VERSION ""

NS_ :

BS_:

BU_:
VAL_TABLE_ Speed ;

BO_ 0 ThrottleMsg: 1 Vector__XXX
 SG_ IntakeValve : 1|7@1+ (1,0) [0|90] "degree" Vector__XXX
 SG_ ThrottlePosition : 0|1@1+ (1,0) [0|1] "Boolean" Vector__XXX

BO_ 256 BrakeMsg: 1 Vector__XXX
 SG_ Brake_Status : 0|1@1+ (1,0) [0|1] "Boolean" Vector__XXX

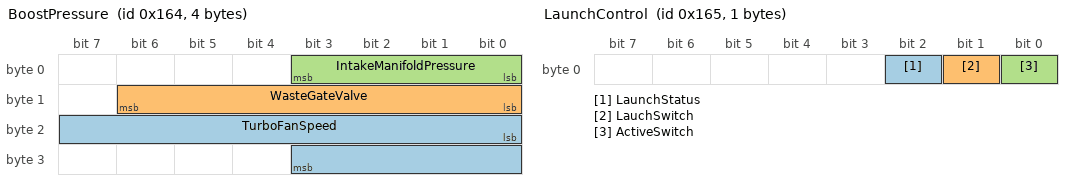
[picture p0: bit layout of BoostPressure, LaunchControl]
BO_ 356 BoostPressure: 4 Vector__XXX
 SG_ TurboFanSpeed : 16|12@1+ (1,0) [0|4000] "rpm" Vector__XXX
 SG_ WasteGateValve : 8|7@1+ (1,0) [0|90] "degree" Vector__XXX
 SG_ IntakeManifoldPressure : 0|4@1+ (1,0) [0|15] "psi" Vector__XXX

BO_ 344 Gear: 1 Vector__XXX
 SG_ GearPosition : 0|3@1+ (1,0) [0|7] "" Vector__XXX

BO_ 357 LaunchControl: 1 Vector__XXX
 SG_ LaunchStatus : 2|1@1+ (1,0) [0|1] "" Vector__XXX
 SG_ LauchSwitch : 1|1@1+ (1,0) [0|1] "Boolean" Vector__XXX
 SG_ ActiveSwitch : 0|1@1+ (1,0) [0|1] "Boolean" Vector__XXX

BO_ 345 RPMMsg: 5 Vector__XXX
 SG_ FuelInjectorTiming : 24|10@1+ (1,0) [0|1000] "ms" Vector__XXX
 SG_ RPM : 0|14@1+ (1,0) [0|8500] "rpm" Vector__XXX

BO_ 352 SpeedMsg: 2 Vector__XXX
 SG_ Speed : 0|9@1+ (1,0) [0|330] "km/h" Vector__XXX
